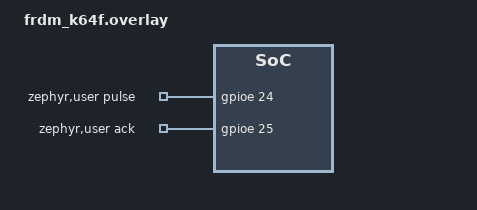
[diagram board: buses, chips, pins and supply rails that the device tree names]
/*
 * SPDX-License-Identifier: Apache-2.0
 *
 * Copyright (c) 2025 Jorge Ramirez-Ortiz <jorge.ramirez@oss.qualcomm.com>
 */

/ {
	zephyr,user {
		pulse_gpios = <&gpioe 24 GPIO_ACTIVE_HIGH>;
		ack_gpios = <&gpioe 25 GPIO_ACTIVE_HIGH>;
	};
};
